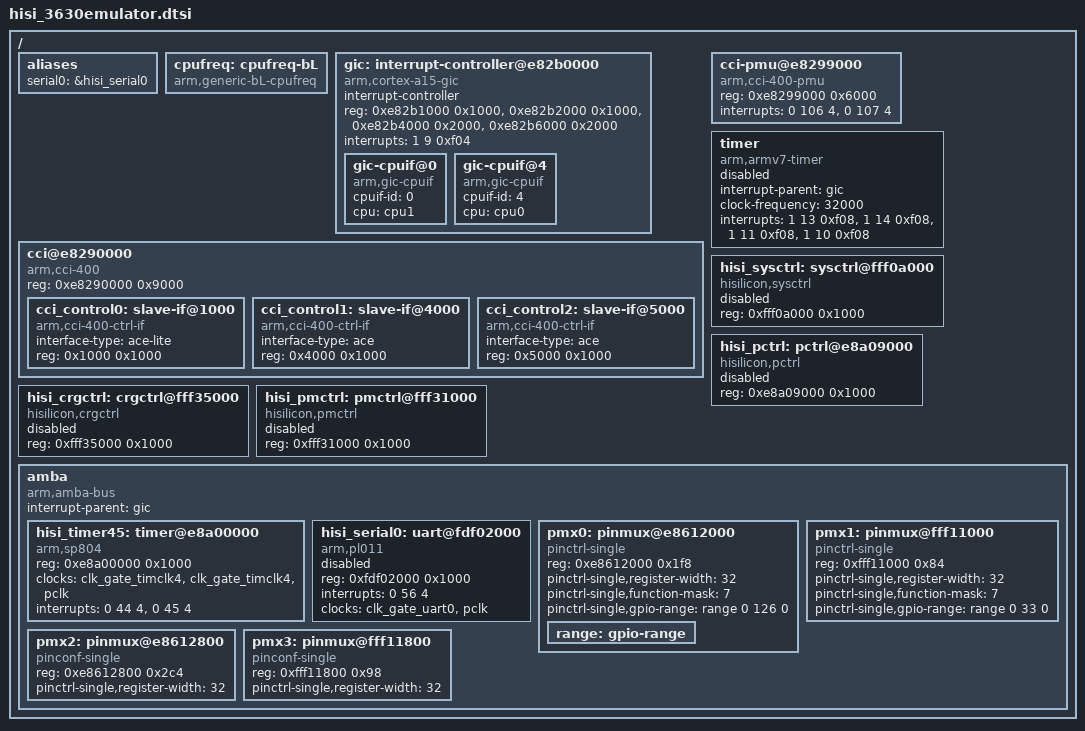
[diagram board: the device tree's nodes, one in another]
/*
 * Hisilicon Ltd. Hi3630FPGA SoC
 *
 * Copyright (C) 2013 Hisilicon Technologies CO., Ltd.
 *
 * This program is free software; you can redistribute it and/or modify
 * it under the terms of the GNU General Public License version 2 as
 * publishhed by the Free Software Foundation.
 */

/include/ "skeleton.dtsi"
/include/ "hisi_3630emulator_clock.dtsi"
/include/ "hisi_3630fpga_gpio.dtsi"

/{
	aliases {
		serial0 = &hisi_serial0;
	};

	/* cpufreq  device */
	cpufreq: cpufreq-bL {
		compatible = "arm,generic-bL-cpufreq";
	};

	gic: interrupt-controller@e82b0000 {
		compatible = "arm,cortex-a15-gic", "arm,cortex-a7-gic";
		#interrupt-cells = <3>;
		#address-cells = <0>;
		interrupt-controller;
		reg =	<0xe82b1000 0x1000>,
			<0xe82b2000 0x1000>,
			<0xe82b4000 0x2000>,
			<0xe82b6000 0x2000>;
		interrupts = <1 9 0xf04>;
		/*In our system, a15 cluster is in range cpuif0/cpuif1/cpuif2/cpuif3
		* a7 cluster is in range cpuif4/cpuif5/cpuif6/cpuif7
		*/
		gic-cpuif@0 {
			compatible = "arm,gic-cpuif";
			cpuif-id = <0>;
			cpu = <&cpu1>;
		};

		gic-cpuif@4 {
			compatible = "arm,gic-cpuif";
			cpuif-id = <4>;
			cpu = <&cpu0>;
		};
	};

        cci@e8290000 {
                compatible = "arm,cci-400";
                #address-cells = <1>;
                #size-cells = <1>;
                reg = <0xe8290000 0x9000>;
                ranges = <0x1000 0xe8291000 0x1000>,
			<0x4000 0xe8294000 0x1000>,
			<0x5000 0xe8295000 0x1000>;

                cci_control0: slave-if@1000 {
                        compatible = "arm,cci-400-ctrl-if";
                        interface-type = "ace-lite";
                        reg = <0x1000 0x1000>;
                };

                cci_control1: slave-if@4000 {
                        compatible = "arm,cci-400-ctrl-if";
                        interface-type = "ace";
                        reg = <0x4000 0x1000>;
                };

                cci_control2: slave-if@5000 {
                        compatible = "arm,cci-400-ctrl-if";
                        interface-type = "ace";
                        reg = <0x5000 0x1000>;
                };
        };

        cci-pmu@e8299000 {
                compatible = "arm,cci-400-pmu";
                reg = <0xe8299000 0x6000>;
                interrupts = <0 106 4>,
                             <0 107 4>;
        };

	timer {
		compatible = "arm,armv7-timer";
		interrupt-parent = <&gic>;
		clock-frequency = <32000>;
		interrupts =
			<1 13 0xf08>,
			<1 14 0xf08>,
			<1 11 0xf08>,
			<1 10 0xf08>;
		status = "disabled";
	};

	hisi_sysctrl: sysctrl@fff0a000 {
		compatible = "hisilicon,sysctrl";
		reg = <0xfff0a000 0x1000>;
		status = "disabled";
	};

	hisi_pctrl: pctrl@e8a09000 {
		compatible = "hisilicon,pctrl";
		reg = <0xe8a09000 0x1000>;
		status = "disabled";
	};

	hisi_crgctrl: crgctrl@fff35000 {
		compatible = "hisilicon,crgctrl";
		reg = <0xfff35000 0x1000>;
		status = "disabled";
	};

	hisi_pmctrl: pmctrl@fff31000 {
		compatible = "hisilicon,pmctrl";
		reg = <0xfff31000 0x1000>;
		status = "disabled";
	};

	amba{
		#address-cells = <1>;
		#size-cells = <1>;
		compatible = "arm,amba-bus";
		interrupt-parent = <&gic>;
		ranges;

		/*hisi_timer01: timer@fff00000 {
			compatible = "arm,sp804", "arm,primecell";
			reg = <0xfff00000 0x1000>;
			clocks = <&clk_gate_timclk0 &clk_gate_timclk0 &pclk>;
			clock-names = "clk_timclk0", "clk_timclk1","apb_pclk";
			interrupts = <0 36 4>,<0 37 4>;
			status = "disabled";
		};*/

		hisi_timer45: timer@e8a00000 {
                        compatible = "arm,sp804", "arm,primecell";
                        reg = <0xe8a00000 0x1000>;
                        clocks = <&clk_gate_timclk4 &clk_gate_timclk4 &pclk>;
                        clock-names = "clk_timclk4", "clk_timclk5","apb_pclk";
                        interrupts = <0 44 4>,<0 45 4>;
                        status = "ok";
                };

		hisi_serial0: uart@fdf02000 {
			compatible = "arm,pl011", "arm,primecell";
			reg = <0xfdf02000 0x1000>;
			interrupts = <0 56 4>;
			clocks = <&clk_gate_uart0 &pclk>;
			clock-names = "clk_gate_uart0", "apb_pclk";
			status = "disabled";
		};


		pmx0: pinmux@e8612000 {
			compatible = "pinctrl-single";
			reg = <0xe8612000 0x1f8>;
			#address-cells = <1>;
			#size-cells = <1>;
			#gpio-range-cells = <3>;
			ranges;

			pinctrl-single,register-width = <32>;
			pinctrl-single,function-mask = <7>;
			/* pin base, nr pins & gpio function */
			pinctrl-single,gpio-range = <&range 0 126 0>;

			range: gpio-range {
				#pinctrl-single,gpio-range-cells = <3>;
			};
		};

		pmx1: pinmux@fff11000 {
			compatible = "pinctrl-single";
			reg = <0xfff11000 0x84>;
			#address-cells = <1>;
			#size-cells = <1>;
			#gpio-range-cells = <3>;
			ranges;

			pinctrl-single,register-width = <32>;
			pinctrl-single,function-mask = <7>;
			/* pin base, nr pins & gpio function */
			pinctrl-single,gpio-range = <&range 0 33 0>;
		};

		pmx2: pinmux@e8612800 {
			compatible = "pinconf-single";
			reg = <0xe8612800 0x2c4>;
			#address-cells = <1>;
			#size-cells = <1>;
			ranges;

			pinctrl-single,register-width = <32>;
		};

		pmx3: pinmux@fff11800 {
			compatible = "pinconf-single";
			reg = <0xfff11800 0x98>;
			#address-cells = <1>;
			#size-cells = <1>;
			ranges;

			pinctrl-single,register-width = <32>;
		};

	};
};
